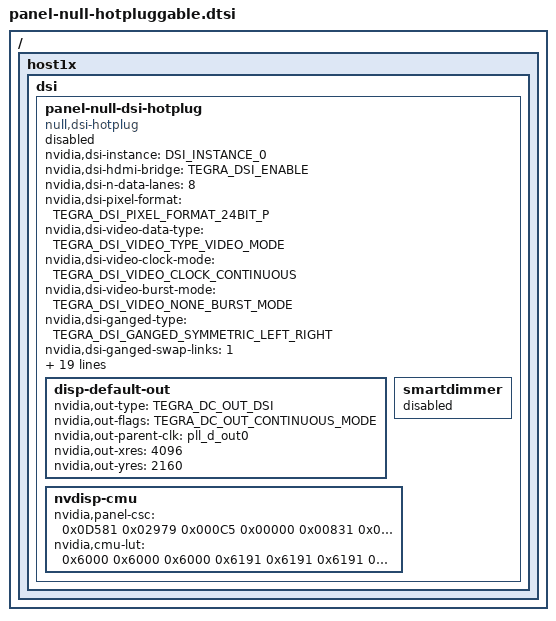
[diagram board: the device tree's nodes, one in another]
/*
 * arch/arm/boot/dts/panel-null-hotpluggable.dtsi
 *
 * Copyright (c) 2017-2019, NVIDIA CORPORATION.  All rights reserved.
 *
 * This program is free software; you can redistribute it and/or modify
 * it under the terms of the GNU General Public License as published by
 * the Free Software Foundation; either version 2 of the License, or
 * (at your option) any later version.
 *
 * This program is distributed in the hope that it will be useful, but WITHOUT
 * ANY WARRANTY; without even the implied warranty of MERCHANTABILITY or
 * FITNESS FOR A PARTICULAR PURPOSE.  See the GNU General Public License for
 * more details.
 *
 * You should have received a copy of the GNU General Public License along
 * with this program; if not, write to the Free Software Foundation, Inc.,
 * 51 Franklin Street, Fifth Floor, Boston, MA  02110-1301, USA.
 */
#include <dt-bindings/display/tegra-dc.h>
#include <dt-bindings/display/tegra-panel.h>

/ {
	host1x {
		dsi {
			panel-null-dsi-hotplug {
				status = "disabled";
				compatible = "null,dsi-hotplug";
				nvidia,dsi-instance = <DSI_INSTANCE_0>;
				nvidia,dsi-hdmi-bridge = <TEGRA_DSI_ENABLE>;
				nvidia,dsi-n-data-lanes = <8>;
				nvidia,dsi-pixel-format = <TEGRA_DSI_PIXEL_FORMAT_24BIT_P>;
				nvidia,dsi-video-data-type = <TEGRA_DSI_VIDEO_TYPE_VIDEO_MODE>;
				nvidia,dsi-video-clock-mode = <TEGRA_DSI_VIDEO_CLOCK_CONTINUOUS>;
				nvidia,dsi-video-burst-mode = <TEGRA_DSI_VIDEO_NONE_BURST_MODE>;
				nvidia,dsi-ganged-type = <TEGRA_DSI_GANGED_SYMMETRIC_LEFT_RIGHT>;
				nvidia,dsi-ganged-swap-links = <1>;
				nvidia,dsi-ganged-write-to-all-links = <1>;
				nvidia,dsi-controller-vs = <DSI_VS_1>;
				nvidia,dsi-virtual-channel = <TEGRA_DSI_VIRTUAL_CHANNEL_0>;
				nvidia,dsi-ulpm-not-support = <TEGRA_DSI_ENABLE>;
				nvidia,dsi-suspend-stop-stream-late = <TEGRA_DSI_ENABLE>;
				nvidia,dsi-power-saving-suspend = <TEGRA_DSI_ENABLE>;
				nvidia,default_color_space = <0>;
				nvidia,dsi-pkt-seq =
					<CMD_VS LEN_SHORT PKT_LP LINE_STOP>,
					<CMD_HS LEN_SHORT PKT_LP LINE_STOP>,
					<CMD_HS LEN_SHORT PKT_LP LINE_STOP>,
					<CMD_HS LEN_SHORT CMD_RGB_24BPP LEN_HACTIVE3 CMD_BLNK LEN_HFP LINE_STOP>,
					<CMD_HS LEN_SHORT PKT_LP LINE_STOP>,
					<CMD_HS LEN_SHORT CMD_RGB_24BPP LEN_HACTIVE3 CMD_BLNK LEN_HFP LINE_STOP>;
				nvidia,edid =
					[ 00 ff ff ff ff ff ff 00 10 ac 68 a0 55 34 4b 31
					  1c 16 01 03 80 35 1e 78 ea 92 65 a6 55 55 9f 28
					  0d 50 54 a5 4b 00 71 4f 81 80 d1 c0 01 01 01 01
					  01 01 01 01 01 01 02 3a 80 18 71 38 2d 40 58 2c
					  45 00 13 2b 21 00 00 1e 00 00 00 ff 00 57 38 56
					  59 39 32 37 41 31 4b 34 55 0a 00 00 00 fc 00 44
					  45 4c 4c 20 53 54 32 34 32 30 4c 0a 00 00 00 fd
					  00 38 4c 1e 53 11 00 0a 20 20 20 20 20 20 01 98];
				disp-default-out {
					nvidia,out-type = <TEGRA_DC_OUT_DSI>;
					nvidia,out-flags = <TEGRA_DC_OUT_CONTINUOUS_MODE>;
					nvidia,out-parent-clk = "pll_d_out0";
					nvidia,out-xres = <4096>;
					nvidia,out-yres = <2160>;
				};
				smartdimmer {
					status = "disabled";
				};
				nvdisp-cmu {
					nvidia,panel-csc = <
						0x0D581 0x02979 0x000C5 0x00000
						0x00831 0x0CAC1 0x0020C 0x00000
						0x00189 0x00625 0x0CC4A 0x00000
						>;
					nvidia,cmu-lut = <
						0x6000 0x6000 0x6000
						0x6191 0x6191 0x6191
						0x6322 0x6322 0x6322
						0x643B 0x643B 0x643B
						0x64BA 0x64BA 0x64BA
						0x6539 0x6539 0x6539
						0x65B8 0x65B8 0x65B8
						0x6637 0x6637 0x6637
						0x66B6 0x66B6 0x66B6
						0x6735 0x6735 0x6735
						0x67B4 0x67B4 0x67B4
						0x6826 0x6826 0x6826
						0x687D 0x687D 0x687D
						0x68D4 0x68D4 0x68D4
						0x692B 0x692B 0x692B
						0x6983 0x6983 0x6983
						0x69DA 0x69DA 0x69DA
						0x6A31 0x6A31 0x6A31
						0x6A88 0x6A88 0x6A88
						0x6AE0 0x6AE0 0x6AE0
						0x6B37 0x6B37 0x6B37
						0x6B8E 0x6B8E 0x6B8E
						0x6BE5 0x6BE5 0x6BE5
						0x6C28 0x6C28 0x6C28
						0x6C5B 0x6C5B 0x6C5B
						0x6C8E 0x6C8E 0x6C8E
						0x6CC1 0x6CC1 0x6CC1
						0x6CF4 0x6CF4 0x6CF4
						0x6D27 0x6D27 0x6D27
						0x6D5A 0x6D5A 0x6D5A
						0x6D8D 0x6D8D 0x6D8D
						0x6DBF 0x6DBF 0x6DBF
						0x6DF2 0x6DF2 0x6DF2
						0x6E25 0x6E25 0x6E25
						0x6E58 0x6E58 0x6E58
						0x6E8B 0x6E8B 0x6E8B
						0x6EBE 0x6EBE 0x6EBE
						0x6EF1 0x6EF1 0x6EF1
						0x6F24 0x6F24 0x6F24
						0x6F57 0x6F57 0x6F57
						0x6F8A 0x6F8A 0x6F8A
						0x6FBD 0x6FBD 0x6FBD
						0x6FF0 0x6FF0 0x6FF0
						0x701A 0x701A 0x701A
						0x7037 0x7037 0x7037
						0x7053 0x7053 0x7053
						0x706F 0x706F 0x706F
						0x708C 0x708C 0x708C
						0x70A8 0x70A8 0x70A8
						0x70C5 0x70C5 0x70C5
						0x70E1 0x70E1 0x70E1
						0x70FE 0x70FE 0x70FE
						0x711A 0x711A 0x711A
						0x7136 0x7136 0x7136
						0x7153 0x7153 0x7153
						0x716F 0x716F 0x716F
						0x718C 0x718C 0x718C
						0x71A8 0x71A8 0x71A8
						0x71C4 0x71C4 0x71C4
						0x71E1 0x71E1 0x71E1
						0x71FD 0x71FD 0x71FD
						0x721A 0x721A 0x721A
						0x7236 0x7236 0x7236
						0x7253 0x7253 0x7253
						0x726F 0x726F 0x726F
						0x728B 0x728B 0x728B
						0x72A8 0x72A8 0x72A8
						0x72C4 0x72C4 0x72C4
						0x72E1 0x72E1 0x72E1
						0x72FD 0x72FD 0x72FD
						0x731A 0x731A 0x731A
						0x7336 0x7336 0x7336
						0x7352 0x7352 0x7352
						0x736F 0x736F 0x736F
						0x738B 0x738B 0x738B
						0x73A8 0x73A8 0x73A8
						0x73C4 0x73C4 0x73C4
						0x73E1 0x73E1 0x73E1
						0x73FD 0x73FD 0x73FD
						0x741B 0x741B 0x741B
						0x743F 0x743F 0x743F
						0x7463 0x7463 0x7463
						0x7486 0x7486 0x7486
						0x74AA 0x74AA 0x74AA
						0x74CE 0x74CE 0x74CE
						0x74F2 0x74F2 0x74F2
						0x7516 0x7516 0x7516
						0x753A 0x753A 0x753A
						0x755D 0x755D 0x755D
						0x7581 0x7581 0x7581
						0x75A5 0x75A5 0x75A5
						0x75C9 0x75C9 0x75C9
						0x75ED 0x75ED 0x75ED
						0x7611 0x7611 0x7611
						0x7634 0x7634 0x7634
						0x7658 0x7658 0x7658
						0x767C 0x767C 0x767C
						0x76A0 0x76A0 0x76A0
						0x76C4 0x76C4 0x76C4
						0x76E8 0x76E8 0x76E8
						0x770B 0x770B 0x770B
						0x772F 0x772F 0x772F
						0x7753 0x7753 0x7753
						0x7777 0x7777 0x7777
						0x779B 0x779B 0x779B
						0x77BF 0x77BF 0x77BF
						0x77E2 0x77E2 0x77E2
						0x7806 0x7806 0x7806
						0x7825 0x7825 0x7825
						0x7840 0x7840 0x7840
						0x785B 0x785B 0x785B
						0x7876 0x7876 0x7876
						0x7891 0x7891 0x7891
						0x78AC 0x78AC 0x78AC
						0x78C7 0x78C7 0x78C7
						0x78E2 0x78E2 0x78E2
						0x78FD 0x78FD 0x78FD
						0x7918 0x7918 0x7918
						0x7933 0x7933 0x7933
						0x794E 0x794E 0x794E
						0x7969 0x7969 0x7969
						0x7984 0x7984 0x7984
						0x799F 0x799F 0x799F
						0x79BA 0x79BA 0x79BA
						0x79D5 0x79D5 0x79D5
						0x79F0 0x79F0 0x79F0
						0x7A0B 0x7A0B 0x7A0B
						0x7A26 0x7A26 0x7A26
						0x7A41 0x7A41 0x7A41
						0x7A5C 0x7A5C 0x7A5C
						0x7A77 0x7A77 0x7A77
						0x7A92 0x7A92 0x7A92
						0x7AAD 0x7AAD 0x7AAD
						0x7AC8 0x7AC8 0x7AC8
						0x7AE3 0x7AE3 0x7AE3
						0x7AFE 0x7AFE 0x7AFE
						0x7B19 0x7B19 0x7B19
						0x7B34 0x7B34 0x7B34
						0x7B4F 0x7B4F 0x7B4F
						0x7B6A 0x7B6A 0x7B6A
						0x7B85 0x7B85 0x7B85
						0x7BA0 0x7BA0 0x7BA0
						0x7BBB 0x7BBB 0x7BBB
						0x7BD5 0x7BD5 0x7BD5
						0x7BF0 0x7BF0 0x7BF0
						0x7C0B 0x7C0B 0x7C0B
						0x7C23 0x7C23 0x7C23
						0x7C35 0x7C35 0x7C35
						0x7C47 0x7C47 0x7C47
						0x7C59 0x7C59 0x7C59
						0x7C6B 0x7C6B 0x7C6B
						0x7C7D 0x7C7D 0x7C7D
						0x7C90 0x7C90 0x7C90
						0x7CA2 0x7CA2 0x7CA2
						0x7CB4 0x7CB4 0x7CB4
						0x7CC6 0x7CC6 0x7CC6
						0x7CD8 0x7CD8 0x7CD8
						0x7CEA 0x7CEA 0x7CEA
						0x7CFC 0x7CFC 0x7CFC
						0x7D0F 0x7D0F 0x7D0F
						0x7D21 0x7D21 0x7D21
						0x7D33 0x7D33 0x7D33
						0x7D45 0x7D45 0x7D45
						0x7D57 0x7D57 0x7D57
						0x7D69 0x7D69 0x7D69
						0x7D7B 0x7D7B 0x7D7B
						0x7D8E 0x7D8E 0x7D8E
						0x7DA0 0x7DA0 0x7DA0
						0x7DB2 0x7DB2 0x7DB2
						0x7DC4 0x7DC4 0x7DC4
						0x7DD6 0x7DD6 0x7DD6
						0x7DE8 0x7DE8 0x7DE8
						0x7DFA 0x7DFA 0x7DFA
						0x7E0D 0x7E0D 0x7E0D
						0x7E1F 0x7E1F 0x7E1F
						0x7E31 0x7E31 0x7E31
						0x7E43 0x7E43 0x7E43
						0x7E55 0x7E55 0x7E55
						0x7E67 0x7E67 0x7E67
						0x7E79 0x7E79 0x7E79
						0x7E8C 0x7E8C 0x7E8C
						0x7E9E 0x7E9E 0x7E9E
						0x7EB0 0x7EB0 0x7EB0
						0x7EC2 0x7EC2 0x7EC2
						0x7ED4 0x7ED4 0x7ED4
						0x7EE6 0x7EE6 0x7EE6
						0x7EF8 0x7EF8 0x7EF8
						0x7F0B 0x7F0B 0x7F0B
						0x7F1D 0x7F1D 0x7F1D
						0x7F2F 0x7F2F 0x7F2F
						0x7F41 0x7F41 0x7F41
						0x7F53 0x7F53 0x7F53
						0x7F65 0x7F65 0x7F65
						0x7F77 0x7F77 0x7F77
						0x7F8A 0x7F8A 0x7F8A
						0x7F9C 0x7F9C 0x7F9C
						0x7FAE 0x7FAE 0x7FAE
						0x7FC0 0x7FC0 0x7FC0
						0x7FD2 0x7FD2 0x7FD2
						0x7FE4 0x7FE4 0x7FE4
						0x7FF7 0x7FF7 0x7FF7
						0x8009 0x8009 0x8009
						0x801B 0x801B 0x801B
						0x802B 0x802B 0x802B
						0x803A 0x803A 0x803A
						0x804A 0x804A 0x804A
						0x8059 0x8059 0x8059
						0x8069 0x8069 0x8069
						0x8078 0x8078 0x8078
						0x8087 0x8087 0x8087
						0x8097 0x8097 0x8097
						0x80A6 0x80A6 0x80A6
						0x80B6 0x80B6 0x80B6
						0x80C5 0x80C5 0x80C5
						0x80D5 0x80D5 0x80D5
						0x80E4 0x80E4 0x80E4
						0x80F4 0x80F4 0x80F4
						0x8103 0x8103 0x8103
						0x8112 0x8112 0x8112
						0x8122 0x8122 0x8122
						0x8131 0x8131 0x8131
						0x8141 0x8141 0x8141
						0x8150 0x8150 0x8150
						0x8160 0x8160 0x8160
						0x816F 0x816F 0x816F
						0x817E 0x817E 0x817E
						0x818E 0x818E 0x818E
						0x819D 0x819D 0x819D
						0x81AD 0x81AD 0x81AD
						0x81BC 0x81BC 0x81BC
						0x81CC 0x81CC 0x81CC
						0x81DB 0x81DB 0x81DB
						0x81EB 0x81EB 0x81EB
						0x81FA 0x81FA 0x81FA
						0x8209 0x8209 0x8209
						0x8219 0x8219 0x8219
						0x8228 0x8228 0x8228
						0x8238 0x8238 0x8238
						0x8247 0x8247 0x8247
						0x8257 0x8257 0x8257
						0x8266 0x8266 0x8266
						0x8275 0x8275 0x8275
						0x8285 0x8285 0x8285
						0x8294 0x8294 0x8294
						0x82A4 0x82A4 0x82A4
						0x82B3 0x82B3 0x82B3
						0x82C3 0x82C3 0x82C3
						0x82D2 0x82D2 0x82D2
						0x82E2 0x82E2 0x82E2
						0x82F1 0x82F1 0x82F1
						0x8300 0x8300 0x8300
						0x8310 0x8310 0x8310
						0x831F 0x831F 0x831F
						0x832F 0x832F 0x832F
						0x833E 0x833E 0x833E
						0x834E 0x834E 0x834E
						0x835D 0x835D 0x835D
						0x836C 0x836C 0x836C
						0x837C 0x837C 0x837C
						0x838B 0x838B 0x838B
						0x839B 0x839B 0x839B
						0x83AA 0x83AA 0x83AA
						0x83BA 0x83BA 0x83BA
						0x83C9 0x83C9 0x83C9
						0x83D8 0x83D8 0x83D8
						0x83E8 0x83E8 0x83E8
						0x83F7 0x83F7 0x83F7
						0x8407 0x8407 0x8407
						0x8416 0x8416 0x8416
						0x8425 0x8425 0x8425
						0x8431 0x8431 0x8431
						0x843D 0x843D 0x843D
						0x8449 0x8449 0x8449
						0x8455 0x8455 0x8455
						0x8462 0x8462 0x8462
						0x846E 0x846E 0x846E
						0x847A 0x847A 0x847A
						0x8486 0x8486 0x8486
						0x8492 0x8492 0x8492
						0x849E 0x849E 0x849E
						0x84AA 0x84AA 0x84AA
						0x84B6 0x84B6 0x84B6
						0x84C2 0x84C2 0x84C2
						0x84CE 0x84CE 0x84CE
						0x84DA 0x84DA 0x84DA
						0x84E7 0x84E7 0x84E7
						0x84F3 0x84F3 0x84F3
						0x84FF 0x84FF 0x84FF
						0x850B 0x850B 0x850B
						0x8517 0x8517 0x8517
						0x8523 0x8523 0x8523
						0x852F 0x852F 0x852F
						0x853B 0x853B 0x853B
						0x8547 0x8547 0x8547
						0x8553 0x8553 0x8553
						0x855F 0x855F 0x855F
						0x856C 0x856C 0x856C
						0x8578 0x8578 0x8578
						0x8584 0x8584 0x8584
						0x8590 0x8590 0x8590
						0x859C 0x859C 0x859C
						0x85A8 0x85A8 0x85A8
						0x85B4 0x85B4 0x85B4
						0x85C0 0x85C0 0x85C0
						0x85CC 0x85CC 0x85CC
						0x85D8 0x85D8 0x85D8
						0x85E4 0x85E4 0x85E4
						0x85F0 0x85F0 0x85F0
						0x85FD 0x85FD 0x85FD
						0x8609 0x8609 0x8609
						0x8615 0x8615 0x8615
						0x8621 0x8621 0x8621
						0x862D 0x862D 0x862D
						0x8639 0x8639 0x8639
						0x8645 0x8645 0x8645
						0x8651 0x8651 0x8651
						0x865D 0x865D 0x865D
						0x8669 0x8669 0x8669
						0x8675 0x8675 0x8675
						0x8682 0x8682 0x8682
						0x868E 0x868E 0x868E
						0x869A 0x869A 0x869A
						0x86A6 0x86A6 0x86A6
						0x86B2 0x86B2 0x86B2
						0x86BE 0x86BE 0x86BE
						0x86CA 0x86CA 0x86CA
						0x86D6 0x86D6 0x86D6
						0x86E2 0x86E2 0x86E2
						0x86EE 0x86EE 0x86EE
						0x86FA 0x86FA 0x86FA
						0x8707 0x8707 0x8707
						0x8713 0x8713 0x8713
						0x871F 0x871F 0x871F
						0x872B 0x872B 0x872B
						0x8737 0x8737 0x8737
						0x8743 0x8743 0x8743
						0x874F 0x874F 0x874F
						0x875B 0x875B 0x875B
						0x8767 0x8767 0x8767
						0x8773 0x8773 0x8773
						0x877F 0x877F 0x877F
						0x878B 0x878B 0x878B
						0x8798 0x8798 0x8798
						0x87A4 0x87A4 0x87A4
						0x87B0 0x87B0 0x87B0
						0x87BC 0x87BC 0x87BC
						0x87C8 0x87C8 0x87C8
						0x87D4 0x87D4 0x87D4
						0x87E0 0x87E0 0x87E0
						0x87EC 0x87EC 0x87EC
						0x87F8 0x87F8 0x87F8
						0x8804 0x8804 0x8804
						0x8810 0x8810 0x8810
						0x881D 0x881D 0x881D
						0x8829 0x8829 0x8829
						0x8834 0x8834 0x8834
						0x883F 0x883F 0x883F
						0x884B 0x884B 0x884B
						0x8856 0x8856 0x8856
						0x8862 0x8862 0x8862
						0x886D 0x886D 0x886D
						0x8879 0x8879 0x8879
						0x8884 0x8884 0x8884
						0x8890 0x8890 0x8890
						0x889B 0x889B 0x889B
						0x88A6 0x88A6 0x88A6
						0x88B2 0x88B2 0x88B2
						0x88BD 0x88BD 0x88BD
						0x88C9 0x88C9 0x88C9
						0x88D4 0x88D4 0x88D4
						0x88E0 0x88E0 0x88E0
						0x88EB 0x88EB 0x88EB
						0x88F6 0x88F6 0x88F6
						0x8902 0x8902 0x8902
						0x890D 0x890D 0x890D
						0x8919 0x8919 0x8919
						0x8924 0x8924 0x8924
						0x8930 0x8930 0x8930
						0x893B 0x893B 0x893B
						0x8947 0x8947 0x8947
						0x8952 0x8952 0x8952
						0x895D 0x895D 0x895D
						0x8969 0x8969 0x8969
						0x8974 0x8974 0x8974
						0x8980 0x8980 0x8980
						0x898B 0x898B 0x898B
						0x8997 0x8997 0x8997
						0x89A2 0x89A2 0x89A2
						0x89AE 0x89AE 0x89AE
						0x89B9 0x89B9 0x89B9
						0x89C4 0x89C4 0x89C4
						0x89D0 0x89D0 0x89D0
						0x89DB 0x89DB 0x89DB
						0x89E7 0x89E7 0x89E7
						0x89F2 0x89F2 0x89F2
						0x89FE 0x89FE 0x89FE
						0x8A09 0x8A09 0x8A09
						0x8A15 0x8A15 0x8A15
						0x8A20 0x8A20 0x8A20
						0x8A2B 0x8A2B 0x8A2B
						0x8A37 0x8A37 0x8A37
						0x8A42 0x8A42 0x8A42
						0x8A4E 0x8A4E 0x8A4E
						0x8A59 0x8A59 0x8A59
						0x8A65 0x8A65 0x8A65
						0x8A70 0x8A70 0x8A70
						0x8A7B 0x8A7B 0x8A7B
						0x8A87 0x8A87 0x8A87
						0x8A92 0x8A92 0x8A92
						0x8A9E 0x8A9E 0x8A9E
						0x8AA9 0x8AA9 0x8AA9
						0x8AB5 0x8AB5 0x8AB5
						0x8AC0 0x8AC0 0x8AC0
						0x8ACC 0x8ACC 0x8ACC
						0x8AD7 0x8AD7 0x8AD7
						0x8AE2 0x8AE2 0x8AE2
						0x8AEE 0x8AEE 0x8AEE
						0x8AF9 0x8AF9 0x8AF9
						0x8B05 0x8B05 0x8B05
						0x8B10 0x8B10 0x8B10
						0x8B1C 0x8B1C 0x8B1C
						0x8B27 0x8B27 0x8B27
						0x8B33 0x8B33 0x8B33
						0x8B3E 0x8B3E 0x8B3E
						0x8B49 0x8B49 0x8B49
						0x8B55 0x8B55 0x8B55
						0x8B60 0x8B60 0x8B60
						0x8B6C 0x8B6C 0x8B6C
						0x8B77 0x8B77 0x8B77
						0x8B83 0x8B83 0x8B83
						0x8B8E 0x8B8E 0x8B8E
						0x8B99 0x8B99 0x8B99
						0x8BA5 0x8BA5 0x8BA5
						0x8BB0 0x8BB0 0x8BB0
						0x8BBC 0x8BBC 0x8BBC
						0x8BC7 0x8BC7 0x8BC7
						0x8BD3 0x8BD3 0x8BD3
						0x8BDE 0x8BDE 0x8BDE
						0x8BEA 0x8BEA 0x8BEA
						0x8BF5 0x8BF5 0x8BF5
						0x8C00 0x8C00 0x8C00
						0x8C0C 0x8C0C 0x8C0C
						0x8C17 0x8C17 0x8C17
						0x8C23 0x8C23 0x8C23
						0x8C2E 0x8C2E 0x8C2E
						0x8C38 0x8C38 0x8C38
						0x8C43 0x8C43 0x8C43
						0x8C4D 0x8C4D 0x8C4D
						0x8C58 0x8C58 0x8C58
						0x8C62 0x8C62 0x8C62
						0x8C6C 0x8C6C 0x8C6C
						0x8C77 0x8C77 0x8C77
						0x8C81 0x8C81 0x8C81
						0x8C8C 0x8C8C 0x8C8C
						0x8C96 0x8C96 0x8C96
						0x8CA0 0x8CA0 0x8CA0
						0x8CAB 0x8CAB 0x8CAB
						0x8CB5 0x8CB5 0x8CB5
						0x8CC0 0x8CC0 0x8CC0
						0x8CCA 0x8CCA 0x8CCA
						0x8CD4 0x8CD4 0x8CD4
						0x8CDF 0x8CDF 0x8CDF
						0x8CE9 0x8CE9 0x8CE9
						0x8CF4 0x8CF4 0x8CF4
						0x8CFE 0x8CFE 0x8CFE
						0x8D09 0x8D09 0x8D09
						0x8D13 0x8D13 0x8D13
						0x8D1D 0x8D1D 0x8D1D
						0x8D28 0x8D28 0x8D28
						0x8D32 0x8D32 0x8D32
						0x8D3D 0x8D3D 0x8D3D
						0x8D47 0x8D47 0x8D47
						0x8D51 0x8D51 0x8D51
						0x8D5C 0x8D5C 0x8D5C
						0x8D66 0x8D66 0x8D66
						0x8D71 0x8D71 0x8D71
						0x8D7B 0x8D7B 0x8D7B
						0x8D85 0x8D85 0x8D85
						0x8D90 0x8D90 0x8D90
						0x8D9A 0x8D9A 0x8D9A
						0x8DA5 0x8DA5 0x8DA5
						0x8DAF 0x8DAF 0x8DAF
						0x8DB9 0x8DB9 0x8DB9
						0x8DC4 0x8DC4 0x8DC4
						0x8DCE 0x8DCE 0x8DCE
						0x8DD9 0x8DD9 0x8DD9
						0x8DE3 0x8DE3 0x8DE3
						0x8DED 0x8DED 0x8DED
						0x8DF8 0x8DF8 0x8DF8
						0x8E02 0x8E02 0x8E02
						0x8E0D 0x8E0D 0x8E0D
						0x8E17 0x8E17 0x8E17
						0x8E22 0x8E22 0x8E22
						0x8E2C 0x8E2C 0x8E2C
						0x8E36 0x8E36 0x8E36
						0x8E41 0x8E41 0x8E41
						0x8E4B 0x8E4B 0x8E4B
						0x8E56 0x8E56 0x8E56
						0x8E60 0x8E60 0x8E60
						0x8E6A 0x8E6A 0x8E6A
						0x8E75 0x8E75 0x8E75
						0x8E7F 0x8E7F 0x8E7F
						0x8E8A 0x8E8A 0x8E8A
						0x8E94 0x8E94 0x8E94
						0x8E9E 0x8E9E 0x8E9E
						0x8EA9 0x8EA9 0x8EA9
						0x8EB3 0x8EB3 0x8EB3
						0x8EBE 0x8EBE 0x8EBE
						0x8EC8 0x8EC8 0x8EC8
						0x8ED2 0x8ED2 0x8ED2
						0x8EDD 0x8EDD 0x8EDD
						0x8EE7 0x8EE7 0x8EE7
						0x8EF2 0x8EF2 0x8EF2
						0x8EFC 0x8EFC 0x8EFC
						0x8F07 0x8F07 0x8F07
						0x8F11 0x8F11 0x8F11
						0x8F1B 0x8F1B 0x8F1B
						0x8F26 0x8F26 0x8F26
						0x8F30 0x8F30 0x8F30
						0x8F3B 0x8F3B 0x8F3B
						0x8F45 0x8F45 0x8F45
						0x8F4F 0x8F4F 0x8F4F
						0x8F5A 0x8F5A 0x8F5A
						0x8F64 0x8F64 0x8F64
						0x8F6F 0x8F6F 0x8F6F
						0x8F79 0x8F79 0x8F79
						0x8F83 0x8F83 0x8F83
						0x8F8E 0x8F8E 0x8F8E
						0x8F98 0x8F98 0x8F98
						0x8FA3 0x8FA3 0x8FA3
						0x8FAD 0x8FAD 0x8FAD
						0x8FB7 0x8FB7 0x8FB7
						0x8FC2 0x8FC2 0x8FC2
						0x8FCC 0x8FCC 0x8FCC
						0x8FD7 0x8FD7 0x8FD7
						0x8FE1 0x8FE1 0x8FE1
						0x8FEB 0x8FEB 0x8FEB
						0x8FF6 0x8FF6 0x8FF6
						0x9000 0x9000 0x9000
						0x900B 0x900B 0x900B
						0x9015 0x9015 0x9015
						0x9020 0x9020 0x9020
						0x902A 0x902A 0x902A
						0x9034 0x9034 0x9034
						0x903E 0x903E 0x903E
						0x9048 0x9048 0x9048
						0x9052 0x9052 0x9052
						0x905C 0x905C 0x905C
						0x9066 0x9066 0x9066
						0x9070 0x9070 0x9070
						0x907A 0x907A 0x907A
						0x9084 0x9084 0x9084
						0x908E 0x908E 0x908E
						0x9098 0x9098 0x9098
						0x90A2 0x90A2 0x90A2
						0x90AC 0x90AC 0x90AC
						0x90B6 0x90B6 0x90B6
						0x90C0 0x90C0 0x90C0
						0x90CA 0x90CA 0x90CA
						0x90D4 0x90D4 0x90D4
						0x90DE 0x90DE 0x90DE
						0x90E8 0x90E8 0x90E8
						0x90F2 0x90F2 0x90F2
						0x90FC 0x90FC 0x90FC
						0x9106 0x9106 0x9106
						0x9110 0x9110 0x9110
						0x911A 0x911A 0x911A
						0x9123 0x9123 0x9123
						0x912D 0x912D 0x912D
						0x9137 0x9137 0x9137
						0x9141 0x9141 0x9141
						0x914B 0x914B 0x914B
						0x9155 0x9155 0x9155
						0x915F 0x915F 0x915F
						0x9169 0x9169 0x9169
						0x9173 0x9173 0x9173
						0x917D 0x917D 0x917D
						0x9187 0x9187 0x9187
						0x9191 0x9191 0x9191
						0x919B 0x919B 0x919B
						0x91A5 0x91A5 0x91A5
						0x91AF 0x91AF 0x91AF
						0x91B9 0x91B9 0x91B9
						0x91C3 0x91C3 0x91C3
						0x91CD 0x91CD 0x91CD
						0x91D7 0x91D7 0x91D7
						0x91E1 0x91E1 0x91E1
						0x91EB 0x91EB 0x91EB
						0x91F5 0x91F5 0x91F5
						0x91FF 0x91FF 0x91FF
						0x9209 0x9209 0x9209
						0x9213 0x9213 0x9213
						0x921D 0x921D 0x921D
						0x9227 0x9227 0x9227
						0x9231 0x9231 0x9231
						0x923B 0x923B 0x923B
						0x9245 0x9245 0x9245
						0x924F 0x924F 0x924F
						0x9259 0x9259 0x9259
						0x9263 0x9263 0x9263
						0x926D 0x926D 0x926D
						0x9277 0x9277 0x9277
						0x9281 0x9281 0x9281
						0x928B 0x928B 0x928B
						0x9295 0x9295 0x9295
						0x929F 0x929F 0x929F
						0x92A8 0x92A8 0x92A8
						0x92B2 0x92B2 0x92B2
						0x92BC 0x92BC 0x92BC
						0x92C6 0x92C6 0x92C6
						0x92D0 0x92D0 0x92D0
						0x92DA 0x92DA 0x92DA
						0x92E4 0x92E4 0x92E4
						0x92EE 0x92EE 0x92EE
						0x92F8 0x92F8 0x92F8
						0x9302 0x9302 0x9302
						0x930C 0x930C 0x930C
						0x9316 0x9316 0x9316
						0x9320 0x9320 0x9320
						0x932A 0x932A 0x932A
						0x9334 0x9334 0x9334
						0x933E 0x933E 0x933E
						0x9348 0x9348 0x9348
						0x9352 0x9352 0x9352
						0x935C 0x935C 0x935C
						0x9366 0x9366 0x9366
						0x9370 0x9370 0x9370
						0x937A 0x937A 0x937A
						0x9384 0x9384 0x9384
						0x938E 0x938E 0x938E
						0x9398 0x9398 0x9398
						0x93A2 0x93A2 0x93A2
						0x93AC 0x93AC 0x93AC
						0x93B6 0x93B6 0x93B6
						0x93C0 0x93C0 0x93C0
						0x93CA 0x93CA 0x93CA
						0x93D4 0x93D4 0x93D4
						0x93DE 0x93DE 0x93DE
						0x93E8 0x93E8 0x93E8
						0x93F2 0x93F2 0x93F2
						0x93FC 0x93FC 0x93FC
						0x9406 0x9406 0x9406
						0x9410 0x9410 0x9410
						0x941A 0x941A 0x941A
						0x9423 0x9423 0x9423
						0x942D 0x942D 0x942D
						0x9437 0x9437 0x9437
						0x9440 0x9440 0x9440
						0x9449 0x9449 0x9449
						0x9451 0x9451 0x9451
						0x945A 0x945A 0x945A
						0x9463 0x9463 0x9463
						0x946C 0x946C 0x946C
						0x9475 0x9475 0x9475
						0x947E 0x947E 0x947E
						0x9486 0x9486 0x9486
						0x948F 0x948F 0x948F
						0x9498 0x9498 0x9498
						0x94A1 0x94A1 0x94A1
						0x94AA 0x94AA 0x94AA
						0x94B3 0x94B3 0x94B3
						0x94BB 0x94BB 0x94BB
						0x94C4 0x94C4 0x94C4
						0x94CD 0x94CD 0x94CD
						0x94D6 0x94D6 0x94D6
						0x94DF 0x94DF 0x94DF
						0x94E8 0x94E8 0x94E8
						0x94F0 0x94F0 0x94F0
						0x94F9 0x94F9 0x94F9
						0x9502 0x9502 0x9502
						0x950B 0x950B 0x950B
						0x9514 0x9514 0x9514
						0x951D 0x951D 0x951D
						0x9525 0x9525 0x9525
						0x952E 0x952E 0x952E
						0x9537 0x9537 0x9537
						0x9540 0x9540 0x9540
						0x9549 0x9549 0x9549
						0x9552 0x9552 0x9552
						0x955A 0x955A 0x955A
						0x9563 0x9563 0x9563
						0x956C 0x956C 0x956C
						0x9575 0x9575 0x9575
						0x957E 0x957E 0x957E
						0x9587 0x9587 0x9587
						0x958F 0x958F 0x958F
						0x9598 0x9598 0x9598
						0x95A1 0x95A1 0x95A1
						0x95AA 0x95AA 0x95AA
						0x95B3 0x95B3 0x95B3
						0x95BC 0x95BC 0x95BC
						0x95C4 0x95C4 0x95C4
						0x95CD 0x95CD 0x95CD
						0x95D6 0x95D6 0x95D6
						0x95DF 0x95DF 0x95DF
						0x95E8 0x95E8 0x95E8
						0x95F1 0x95F1 0x95F1
						0x95F9 0x95F9 0x95F9
						0x9602 0x9602 0x9602
						0x960B 0x960B 0x960B
						0x9614 0x9614 0x9614
						0x961D 0x961D 0x961D
						0x9626 0x9626 0x9626
						0x962E 0x962E 0x962E
						0x9637 0x9637 0x9637
						0x9640 0x9640 0x9640
						0x9649 0x9649 0x9649
						0x9652 0x9652 0x9652
						0x965B 0x965B 0x965B
						0x9663 0x9663 0x9663
						0x966C 0x966C 0x966C
						0x9675 0x9675 0x9675
						0x967E 0x967E 0x967E
						0x9687 0x9687 0x9687
						0x9690 0x9690 0x9690
						0x9698 0x9698 0x9698
						0x96A1 0x96A1 0x96A1
						0x96AA 0x96AA 0x96AA
						0x96B3 0x96B3 0x96B3
						0x96BC 0x96BC 0x96BC
						0x96C5 0x96C5 0x96C5
						0x96CD 0x96CD 0x96CD
						0x96D6 0x96D6 0x96D6
						0x96DF 0x96DF 0x96DF
						0x96E8 0x96E8 0x96E8
						0x96F1 0x96F1 0x96F1
						0x96F9 0x96F9 0x96F9
						0x9702 0x9702 0x9702
						0x970B 0x970B 0x970B
						0x9714 0x9714 0x9714
						0x971D 0x971D 0x971D
						0x9726 0x9726 0x9726
						0x972E 0x972E 0x972E
						0x9737 0x9737 0x9737
						0x9740 0x9740 0x9740
						0x9749 0x9749 0x9749
						0x9752 0x9752 0x9752
						0x975B 0x975B 0x975B
						0x9763 0x9763 0x9763
						0x976C 0x976C 0x976C
						0x9775 0x9775 0x9775
						0x977E 0x977E 0x977E
						0x9787 0x9787 0x9787
						0x9790 0x9790 0x9790
						0x9798 0x9798 0x9798
						0x97A1 0x97A1 0x97A1
						0x97AA 0x97AA 0x97AA
						0x97B3 0x97B3 0x97B3
						0x97BC 0x97BC 0x97BC
						0x97C5 0x97C5 0x97C5
						0x97CD 0x97CD 0x97CD
						0x97D6 0x97D6 0x97D6
						0x97DF 0x97DF 0x97DF
						0x97E8 0x97E8 0x97E8
						0x97F1 0x97F1 0x97F1
						0x97FA 0x97FA 0x97FA
						0x9802 0x9802 0x9802
						0x980B 0x980B 0x980B
						0x9814 0x9814 0x9814
						0x981D 0x981D 0x981D
						0x9826 0x9826 0x9826
						0x982F 0x982F 0x982F
						0x9837 0x9837 0x9837
						0x983F 0x983F 0x983F
						0x9847 0x9847 0x9847
						0x984F 0x984F 0x984F
						0x9857 0x9857 0x9857
						0x985F 0x985F 0x985F
						0x9867 0x9867 0x9867
						0x986E 0x986E 0x986E
						0x9876 0x9876 0x9876
						0x987E 0x987E 0x987E
						0x9886 0x9886 0x9886
						0x988E 0x988E 0x988E
						0x9896 0x9896 0x9896
						0x989E 0x989E 0x989E
						0x98A5 0x98A5 0x98A5
						0x98AD 0x98AD 0x98AD
						0x98B5 0x98B5 0x98B5
						0x98BD 0x98BD 0x98BD
						0x98C5 0x98C5 0x98C5
						0x98CD 0x98CD 0x98CD
						0x98D5 0x98D5 0x98D5
						0x98DC 0x98DC 0x98DC
						0x98E4 0x98E4 0x98E4
						0x98EC 0x98EC 0x98EC
						0x98F4 0x98F4 0x98F4
						0x98FC 0x98FC 0x98FC
						0x9904 0x9904 0x9904
						0x990C 0x990C 0x990C
						0x9913 0x9913 0x9913
						0x991B 0x991B 0x991B
						0x9923 0x9923 0x9923
						0x992B 0x992B 0x992B
						0x9933 0x9933 0x9933
						0x993B 0x993B 0x993B
						0x9943 0x9943 0x9943
						0x994A 0x994A 0x994A
						0x9952 0x9952 0x9952
						0x995A 0x995A 0x995A
						0x9962 0x9962 0x9962
						0x996A 0x996A 0x996A
						0x9972 0x9972 0x9972
						0x997A 0x997A 0x997A
						0x9981 0x9981 0x9981
						0x9989 0x9989 0x9989
						0x9991 0x9991 0x9991
						0x9999 0x9999 0x9999
						0x99A1 0x99A1 0x99A1
						0x99A9 0x99A9 0x99A9
						0x99B1 0x99B1 0x99B1
						0x99B8 0x99B8 0x99B8
						0x99C0 0x99C0 0x99C0
						0x99C8 0x99C8 0x99C8
						0x99D0 0x99D0 0x99D0
						0x99D8 0x99D8 0x99D8
						0x99E0 0x99E0 0x99E0
						0x99E8 0x99E8 0x99E8
						0x99EF 0x99EF 0x99EF
						0x99F7 0x99F7 0x99F7
						0x99FF 0x99FF 0x99FF
						0x9A07 0x9A07 0x9A07
						0x9A0F 0x9A0F 0x9A0F
						0x9A17 0x9A17 0x9A17
						0x9A1F 0x9A1F 0x9A1F
						0x9A26 0x9A26 0x9A26
						0x9A2E 0x9A2E 0x9A2E
						0x9A36 0x9A36 0x9A36
						0x9A3E 0x9A3E 0x9A3E
						0x9A46 0x9A46 0x9A46
						0x9A4E 0x9A4E 0x9A4E
						0x9A56 0x9A56 0x9A56
						0x9A5D 0x9A5D 0x9A5D
						0x9A65 0x9A65 0x9A65
						0x9A6D 0x9A6D 0x9A6D
						0x9A75 0x9A75 0x9A75
						0x9A7D 0x9A7D 0x9A7D
						0x9A85 0x9A85 0x9A85
						0x9A8D 0x9A8D 0x9A8D
						0x9A94 0x9A94 0x9A94
						0x9A9C 0x9A9C 0x9A9C
						0x9AA4 0x9AA4 0x9AA4
						0x9AAC 0x9AAC 0x9AAC
						0x9AB4 0x9AB4 0x9AB4
						0x9ABC 0x9ABC 0x9ABC
						0x9AC4 0x9AC4 0x9AC4
						0x9ACB 0x9ACB 0x9ACB
						0x9AD3 0x9AD3 0x9AD3
						0x9ADB 0x9ADB 0x9ADB
						0x9AE3 0x9AE3 0x9AE3
						0x9AEB 0x9AEB 0x9AEB
						0x9AF3 0x9AF3 0x9AF3
						0x9AFB 0x9AFB 0x9AFB
						0x9B02 0x9B02 0x9B02
						0x9B0A 0x9B0A 0x9B0A
						0x9B12 0x9B12 0x9B12
						0x9B1A 0x9B1A 0x9B1A
						0x9B22 0x9B22 0x9B22
						0x9B2A 0x9B2A 0x9B2A
						0x9B32 0x9B32 0x9B32
						0x9B39 0x9B39 0x9B39
						0x9B41 0x9B41 0x9B41
						0x9B49 0x9B49 0x9B49
						0x9B51 0x9B51 0x9B51
						0x9B59 0x9B59 0x9B59
						0x9B61 0x9B61 0x9B61
						0x9B69 0x9B69 0x9B69
						0x9B70 0x9B70 0x9B70
						0x9B78 0x9B78 0x9B78
						0x9B80 0x9B80 0x9B80
						0x9B88 0x9B88 0x9B88
						0x9B90 0x9B90 0x9B90
						0x9B98 0x9B98 0x9B98
						0x9BA0 0x9BA0 0x9BA0
						0x9BA7 0x9BA7 0x9BA7
						0x9BAF 0x9BAF 0x9BAF
						0x9BB7 0x9BB7 0x9BB7
						0x9BBF 0x9BBF 0x9BBF
						0x9BC7 0x9BC7 0x9BC7
						0x9BCF 0x9BCF 0x9BCF
						0x9BD7 0x9BD7 0x9BD7
						0x9BDE 0x9BDE 0x9BDE
						0x9BE6 0x9BE6 0x9BE6
						0x9BEE 0x9BEE 0x9BEE
						0x9BF6 0x9BF6 0x9BF6
						0x9BFE 0x9BFE 0x9BFE
						0x9C06 0x9C06 0x9C06
						0x9C0E 0x9C0E 0x9C0E
						0x9C15 0x9C15 0x9C15
						0x9C1D 0x9C1D 0x9C1D
						0x9C25 0x9C25 0x9C25
						0x9C2D 0x9C2D 0x9C2D
						0x9C35 0x9C35 0x9C35
						0x9C3D 0x9C3D 0x9C3D
						0x9C44 0x9C44 0x9C44
						0x9C4B 0x9C4B 0x9C4B
						0x9C53 0x9C53 0x9C53
						0x9C5A 0x9C5A 0x9C5A
						0x9C61 0x9C61 0x9C61
						0x9C69 0x9C69 0x9C69
						0x9C70 0x9C70 0x9C70
						0x9C77 0x9C77 0x9C77
						0x9C7F 0x9C7F 0x9C7F
						0x9C86 0x9C86 0x9C86
						0x9C8D 0x9C8D 0x9C8D
						0x9C95 0x9C95 0x9C95
						0x9C9C 0x9C9C 0x9C9C
						0x9CA3 0x9CA3 0x9CA3
						0x9CAB 0x9CAB 0x9CAB
						0x9CB2 0x9CB2 0x9CB2
						0x9CB9 0x9CB9 0x9CB9
						0x9CC1 0x9CC1 0x9CC1
						0x9CC8 0x9CC8 0x9CC8
						0x9CCF 0x9CCF 0x9CCF
						0x9CD7 0x9CD7 0x9CD7
						0x9CDE 0x9CDE 0x9CDE
						0x9CE5 0x9CE5 0x9CE5
						0x9CED 0x9CED 0x9CED
						0x9CF4 0x9CF4 0x9CF4
						0x9CFB 0x9CFB 0x9CFB
						0x9D03 0x9D03 0x9D03
						0x9D0A 0x9D0A 0x9D0A
						0x9D12 0x9D12 0x9D12
						0x9D19 0x9D19 0x9D19
						0x9D20 0x9D20 0x9D20
						0x9D28 0x9D28 0x9D28
						0x9D2F 0x9D2F 0x9D2F
						0x9D36 0x9D36 0x9D36
						0x9D3E 0x9D3E 0x9D3E
						0x9D45 0x9D45 0x9D45
						0x9D4C 0x9D4C 0x9D4C
						0x9D54 0x9D54 0x9D54
						0x9D5B 0x9D5B 0x9D5B
						0x9D62 0x9D62 0x9D62
						0x9D6A 0x9D6A 0x9D6A
						0x9D71 0x9D71 0x9D71
						0x9D78 0x9D78 0x9D78
						0x9D80 0x9D80 0x9D80
						0x9D87 0x9D87 0x9D87
						0x9D8E 0x9D8E 0x9D8E
						0x9D96 0x9D96 0x9D96
						0x9D9D 0x9D9D 0x9D9D
						0x9DA4 0x9DA4 0x9DA4
						0x9DAC 0x9DAC 0x9DAC
						0x9DB3 0x9DB3 0x9DB3
						0x9DBA 0x9DBA 0x9DBA
						0x9DC2 0x9DC2 0x9DC2
						0x9DC9 0x9DC9 0x9DC9
						0x9DD0 0x9DD0 0x9DD0
						0x9DD8 0x9DD8 0x9DD8
						0x9DDF 0x9DDF 0x9DDF
						0x9DE6 0x9DE6 0x9DE6
						0x9DEE 0x9DEE 0x9DEE
						0x9DF5 0x9DF5 0x9DF5
						0x9DFC 0x9DFC 0x9DFC
						0x9E04 0x9E04 0x9E04
						0x9E0B 0x9E0B 0x9E0B
						0x9E13 0x9E13 0x9E13
						0x9E1A 0x9E1A 0x9E1A
						0x9E21 0x9E21 0x9E21
						0x9E29 0x9E29 0x9E29
						0x9E30 0x9E30 0x9E30
						0x9E37 0x9E37 0x9E37
						0x9E3F 0x9E3F 0x9E3F
						0x9E46 0x9E46 0x9E46
						0x9E4D 0x9E4D 0x9E4D
						0x9E55 0x9E55 0x9E55
						0x9E5C 0x9E5C 0x9E5C
						0x9E63 0x9E63 0x9E63
						0x9E6B 0x9E6B 0x9E6B
						0x9E72 0x9E72 0x9E72
						0x9E79 0x9E79 0x9E79
						0x9E81 0x9E81 0x9E81
						0x9E88 0x9E88 0x9E88
						0x9E8F 0x9E8F 0x9E8F
						0x9E97 0x9E97 0x9E97
						0x9E9E 0x9E9E 0x9E9E
						0x9EA5 0x9EA5 0x9EA5
						0x9EAD 0x9EAD 0x9EAD
						0x9EB4 0x9EB4 0x9EB4
						0x9EBB 0x9EBB 0x9EBB
						0x9EC3 0x9EC3 0x9EC3
						0x9ECA 0x9ECA 0x9ECA
						0x9ED1 0x9ED1 0x9ED1
						0x9ED9 0x9ED9 0x9ED9
						0x9EE0 0x9EE0 0x9EE0
						0x9EE7 0x9EE7 0x9EE7
						0x9EEF 0x9EEF 0x9EEF
						0x9EF6 0x9EF6 0x9EF6
						0x9EFD 0x9EFD 0x9EFD
						0x9F05 0x9F05 0x9F05
						0x9F0C 0x9F0C 0x9F0C
						0x9F14 0x9F14 0x9F14
						0x9F1B 0x9F1B 0x9F1B
						0x9F22 0x9F22 0x9F22
						0x9F2A 0x9F2A 0x9F2A
						0x9F31 0x9F31 0x9F31
						0x9F38 0x9F38 0x9F38
						0x9F40 0x9F40 0x9F40
						0x9F47 0x9F47 0x9F47
						0x9F4E 0x9F4E 0x9F4E
						0x9F56 0x9F56 0x9F56
						0x9F5D 0x9F5D 0x9F5D
						0x9F64 0x9F64 0x9F64
						0x9F6C 0x9F6C 0x9F6C
						0x9F73 0x9F73 0x9F73
						0x9F7A 0x9F7A 0x9F7A
						0x9F82 0x9F82 0x9F82
						0x9F89 0x9F89 0x9F89
						0x9F90 0x9F90 0x9F90
						0x9F98 0x9F98 0x9F98
						0x9F9F 0x9F9F 0x9F9F
						0x9FA6 0x9FA6 0x9FA6
						0x9FAE 0x9FAE 0x9FAE
						0x9FB5 0x9FB5 0x9FB5
						0x9FBC 0x9FBC 0x9FBC
						0x9FC4 0x9FC4 0x9FC4
						0x9FCB 0x9FCB 0x9FCB
						0x9FD2 0x9FD2 0x9FD2
						0x9FDA 0x9FDA 0x9FDA
						0x9FE1 0x9FE1 0x9FE1
						0x9FE8 0x9FE8 0x9FE8
						0x9FF0 0x9FF0 0x9FF0
						0x9FF7 0x9FF7 0x9FF7
						0x9FFF 0x9FFF 0x9FFF
						>;
				};
			};
		};
	};
};
